# RCSS_PCR register map
Vendor: Texas Instruments
Registers are 32-bit, read-write, no defined reset value unless marked. A register's access mark holds for its fields unless they carry their own. Offsets are as the file gives them; [hi:lo] are bit positions; {n}, {i} and the like mark numbered series.

## RCSS_PCR (part 2 of 2)
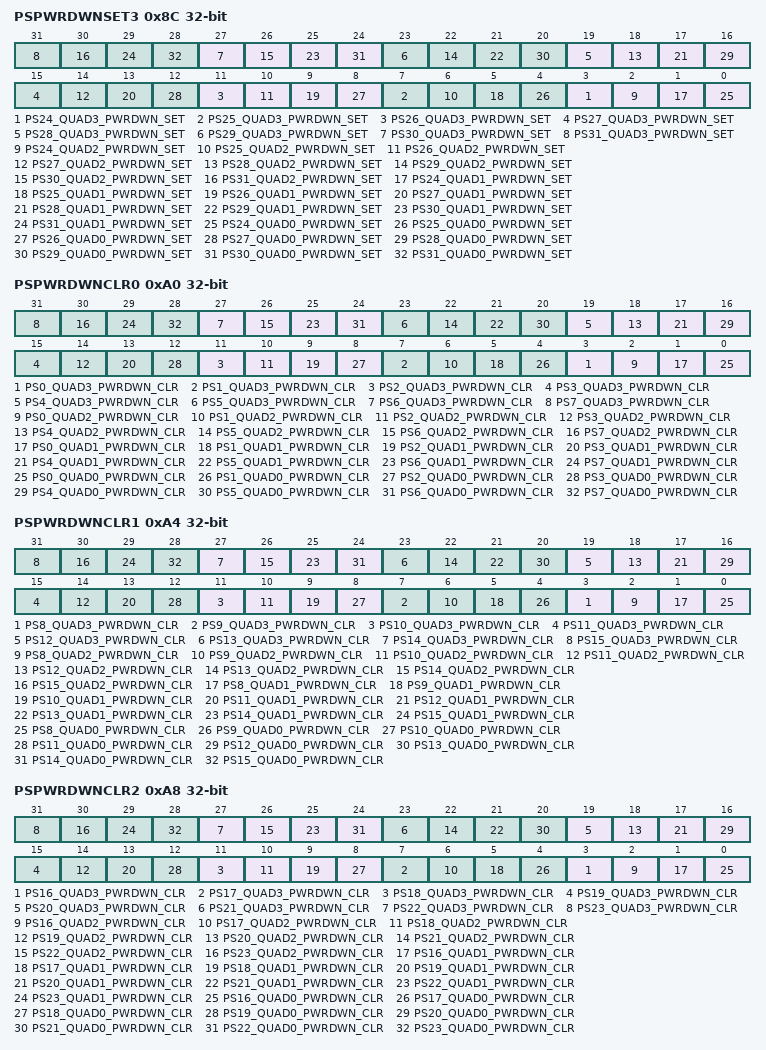
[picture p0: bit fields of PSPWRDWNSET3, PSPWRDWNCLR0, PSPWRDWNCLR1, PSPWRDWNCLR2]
0x8C PSPWRDWNSET3 — Set-only register to powerdown the applicable peripherals in the 32 quadrants of PS24 to PS31
  [4n-93] PS{n}_QUAD3_PWRDWN_SET (n=24..31) — Readable in both user and privileged modes. 1 = The clock to the peripheral starting at quadrant ‘m’ of the peripheral frame ‘n’ needs to be powered down. 0 = The clock to the peripheral starting at quadrant ‘m’ of the peripheral frame ‘n’ needs to be powered up. Writable only in privileged mode 1 = Sets the corresponding bit in PSPWRDWNSET3 and PSPWRDWNCLR3 registers 0 = Has no effect
  [4n-94] PS{n}_QUAD2_PWRDWN_SET (n=24..31) — Readable in both user and privileged modes. 1 = The clock to the peripheral starting at quadrant ‘m’ of the peripheral frame ‘n’ needs to be powered down. 0 = The clock to the peripheral starting at quadrant ‘m’ of the peripheral frame ‘n’ needs to be powered up. Writable only in privileged mode 1 = Sets the corresponding bit in PSPWRDWNSET3 and PSPWRDWNCLR3 registers 0 = Has no effect
  [4n-95] PS{n}_QUAD1_PWRDWN_SET (n=24..31) — Readable in both user and privileged modes. 1 = The clock to the peripheral starting at quadrant ‘m’ of the peripheral frame ‘n’ needs to be powered down. 0 = The clock to the peripheral starting at quadrant ‘m’ of the peripheral frame ‘n’ needs to be powered up. Writable only in privileged mode 1 = Sets the corresponding bit in PSPWRDWNSET3 and PSPWRDWNCLR3 registers 0 = Has no effect
  [4n-96] PS{n}_QUAD0_PWRDWN_SET (n=24..31) — Readable in both user and privileged modes. 1 = The clock to the peripheral starting at quadrant ‘m’ of the peripheral frame ‘n’ needs to be powered down. 0 = The clock to the peripheral starting at quadrant ‘m’ of the peripheral frame ‘n’ needs to be powered up. Writable only in privileged mode 1 = Sets the corresponding bit in PSPWRDWNSET3 and PSPWRDWNCLR3 registers 0 = Has no effect
0xA0 PSPWRDWNCLR0 — Clear-only register to deassert powerdown bits of the applicable peripherals in the 32 quadrants of PS0 to PS7
  [4n+3] PS{n}_QUAD3_PWRDWN_CLR (n=0..7) — Readable in both user and privileged modes. 1 = The clock to the peripheral starting at quadrant ‘m’ of the peripheral frame ‘n’ needs to be powered down. 0 = The clock to the peripheral starting at quadrant ‘m’ of the peripheral frame ‘n’ needs to be powered up. Writable only in privileged mode 1 = Clears the corresponding bit in PSPWRDWNSET0 and PSPWRDWNCLR0 registers 0 = Has no effect
  [4n+2] PS{n}_QUAD2_PWRDWN_CLR (n=0..7) — Readable in both user and privileged modes. 1 = The clock to the peripheral starting at quadrant ‘m’ of the peripheral frame ‘n’ needs to be powered down. 0 = The clock to the peripheral starting at quadrant ‘m’ of the peripheral frame ‘n’ needs to be powered up. Writable only in privileged mode 1 = Clears the corresponding bit in PSPWRDWNSET0 and PSPWRDWNCLR0 registers 0 = Has no effect
  [4n+1] PS{n}_QUAD1_PWRDWN_CLR (n=0..7) — Readable in both user and privileged modes. 1 = The clock to the peripheral starting at quadrant ‘m’ of the peripheral frame ‘n’ needs to be powered down. 0 = The clock to the peripheral starting at quadrant ‘m’ of the peripheral frame ‘n’ needs to be powered up. Writable only in privileged mode 1 = Clears the corresponding bit in PSPWRDWNSET0 and PSPWRDWNCLR0 registers 0 = Has no effect
  [4n] PS{n}_QUAD0_PWRDWN_CLR (n=0..7) — Readable in both user and privileged modes. 1 = The clock to the peripheral starting at quadrant ‘m’ of the peripheral frame ‘n’ needs to be powered down. 0 = The clock to the peripheral starting at quadrant ‘m’ of the peripheral frame ‘n’ needs to be powered up. Writable only in privileged mode 1 = Clears the corresponding bit in PSPWRDWNSET0 and PSPWRDWNCLR0 registers 0 = Has no effect
0xA4 PSPWRDWNCLR1 — Clear-only register to deassert powerdown bits of the applicable peripherals in the 32 quadrants of PS8 to PS15
  [4n-29] PS{n}_QUAD3_PWRDWN_CLR (n=8..15) — Readable in both user and privileged modes. 1 = The clock to the peripheral starting at quadrant ‘m’ of the peripheral frame ‘n’ needs to be powered down. 0 = The clock to the peripheral starting at quadrant ‘m’ of the peripheral frame ‘n’ needs to be powered up. Writable only in privileged mode 1 = Clears the corresponding bit in PSPWRDWNCLR1 and PSPWRDWNCLR1 registers 0 = Has no effect
  [4n-30] PS{n}_QUAD2_PWRDWN_CLR (n=8..15) — Readable in both user and privileged modes. 1 = The clock to the peripheral starting at quadrant ‘m’ of the peripheral frame ‘n’ needs to be powered down. 0 = The clock to the peripheral starting at quadrant ‘m’ of the peripheral frame ‘n’ needs to be powered up. Writable only in privileged mode 1 = Clears the corresponding bit in PSPWRDWNCLR1 and PSPWRDWNCLR1 registers 0 = Has no effect
  [4n-31] PS{n}_QUAD1_PWRDWN_CLR (n=8..15) — Readable in both user and privileged modes. 1 = The clock to the peripheral starting at quadrant ‘m’ of the peripheral frame ‘n’ needs to be powered down. 0 = The clock to the peripheral starting at quadrant ‘m’ of the peripheral frame ‘n’ needs to be powered up. Writable only in privileged mode 1 = Clears the corresponding bit in PSPWRDWNCLR1 and PSPWRDWNCLR1 registers 0 = Has no effect
  [4n-32] PS{n}_QUAD0_PWRDWN_CLR (n=8..15) — Readable in both user and privileged modes. 1 = The clock to the peripheral starting at quadrant ‘m’ of the peripheral frame ‘n’ needs to be powered down. 0 = The clock to the peripheral starting at quadrant ‘m’ of the peripheral frame ‘n’ needs to be powered up. Writable only in privileged mode 1 = Clears the corresponding bit in PSPWRDWNCLR1 and PSPWRDWNCLR1 registers 0 = Has no effect
0xA8 PSPWRDWNCLR2 — Clear-only register to deassert powerdown bits of the applicable peripherals in the 32 quadrants of PS16 to PS23
  [4n-61] PS{n}_QUAD3_PWRDWN_CLR (n=16..23) — Readable in both user and privileged modes. 1 = The clock to the peripheral starting at quadrant ‘m’ of the peripheral frame ‘n’ needs to be powered down. 0 = The clock to the peripheral starting at quadrant ‘m’ of the peripheral frame ‘n’ needs to be powered up. Writable only in privileged mode 1 = Clears the corresponding bit in PSPWRDWNSET2 and PSPWRDWNCLR2 registers 0 = Has no effect
  [4n-62] PS{n}_QUAD2_PWRDWN_CLR (n=16..23) — Readable in both user and privileged modes. 1 = The clock to the peripheral starting at quadrant ‘m’ of the peripheral frame ‘n’ needs to be powered down. 0 = The clock to the peripheral starting at quadrant ‘m’ of the peripheral frame ‘n’ needs to be powered up. Writable only in privileged mode 1 = Clears the corresponding bit in PSPWRDWNSET2 and PSPWRDWNCLR2 registers 0 = Has no effect
  [4n-63] PS{n}_QUAD1_PWRDWN_CLR (n=16..23) — Readable in both user and privileged modes. 1 = The clock to the peripheral starting at quadrant ‘m’ of the peripheral frame ‘n’ needs to be powered down. 0 = The clock to the peripheral starting at quadrant ‘m’ of the peripheral frame ‘n’ needs to be powered up. Writable only in privileged mode 1 = Clears the corresponding bit in PSPWRDWNSET2 and PSPWRDWNCLR2 registers 0 = Has no effect
  [4n-64] PS{n}_QUAD0_PWRDWN_CLR (n=16..23) — Readable in both user and privileged modes. 1 = The clock to the peripheral starting at quadrant ‘m’ of the peripheral frame ‘n’ needs to be powered down. 0 = The clock to the peripheral starting at quadrant ‘m’ of the peripheral frame ‘n’ needs to be powered up. Writable only in privileged mode 1 = Clears the corresponding bit in PSPWRDWNSET2 and PSPWRDWNCLR2 registers 0 = Has no effect
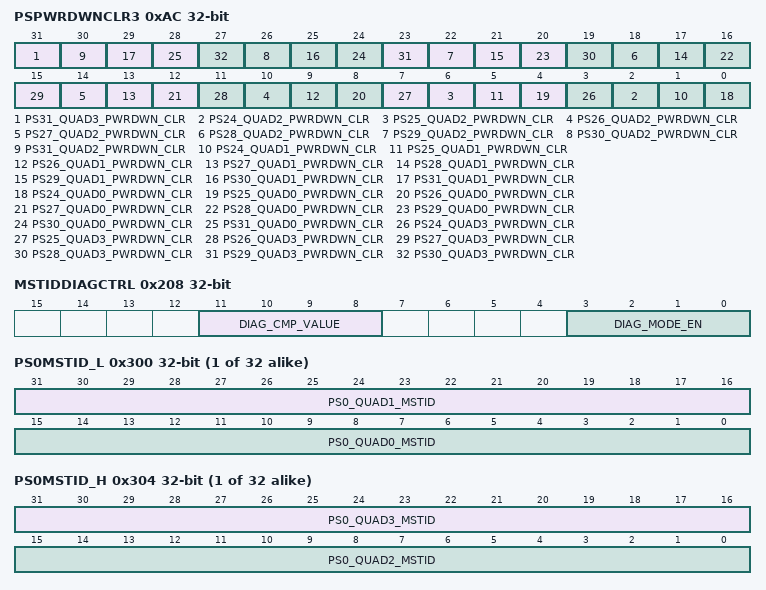
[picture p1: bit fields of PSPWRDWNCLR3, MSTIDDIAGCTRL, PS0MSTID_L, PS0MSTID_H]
0xAC PSPWRDWNCLR3 — Clear-only register to deassert powerdown bits of the applicable peripherals in the 32 quadrants of PS24 to PS31
  [31] PS31_QUAD3_PWRDWN_CLR
  [4n-94] PS{n}_QUAD2_PWRDWN_CLR (n=24..31) — Readable in both user and privileged modes. 1 = The clock to the peripheral starting at quadrant ‘m’ of the peripheral frame ‘n’ needs to be powered down. 0 = The clock to the peripheral starting at quadrant ‘m’ of the peripheral frame ‘n’ needs to be powered up. Writable only in privileged mode 1 = Clears the corresponding bit in PSPWRDWNSET3 and PSPWRDWNCLR3 registers 0 = Has no effect
  [4n-95] PS{n}_QUAD1_PWRDWN_CLR (n=24..31) — Readable in both user and privileged modes. 1 = The clock to the peripheral starting at quadrant ‘m’ of the peripheral frame ‘n’ needs to be powered down. 0 = The clock to the peripheral starting at quadrant ‘m’ of the peripheral frame ‘n’ needs to be powered up. Writable only in privileged mode 1 = Clears the corresponding bit in PSPWRDWNSET3 and PSPWRDWNCLR3 registers 0 = Has no effect
  [4n-96] PS{n}_QUAD0_PWRDWN_CLR (n=24..31) — Readable in both user and privileged modes. 1 = The clock to the peripheral starting at quadrant ‘m’ of the peripheral frame ‘n’ needs to be powered down. 0 = The clock to the peripheral starting at quadrant ‘m’ of the peripheral frame ‘n’ needs to be powered up. Writable only in privileged mode 1 = Clears the corresponding bit in PSPWRDWNSET3 and PSPWRDWNCLR3 registers 0 = Has no effect
  [4n-93] PS{n}_QUAD3_PWRDWN_CLR (n=24..30) — Readable in both user and privileged modes. 1 = The clock to the peripheral starting at quadrant ‘m’ of the peripheral frame ‘n’ needs to be powered down. 0 = The clock to the peripheral starting at quadrant ‘m’ of the peripheral frame ‘n’ needs to be powered up. Writable only in privileged mode 1 = Clears the corresponding bit in PSPWRDWNSET3 and PSPWRDWNCLR3 registers 0 = Has no effect
0xC0 PDPWRDWNSET access per field — Set-only register to powerdown the debug frame
  [0] PD_PWRDWN_SET rw — Readable in both user and privileged modes. 1 = Clock to the debug frame needs to be powered down. 0 = Clock to the debug frame needs to be powered up. Writable only in privileged mode 1 = Bit 0 when written 1, will get set in both PDPWRDWNSET and PDPWRDWNCLR registers. The other bits are not affected. 0 = Has no effect
0xC4 PDPWRDWNCLR access per field — Clear-only register to deassert the debug frame’s powerdown bit
  [0] PD_PWRDWN_CLR rw — Readable in both user and privileged modes. 1 = The clock to the debug frame needs to be powered down. 0 = The clock to the debug frame needs to be powered up. Writable only in privileged mode 1 = Bit 0 when written 1, will get cleared in both PDPWRDWNSET and PDPWRDWNCLR registers. The other bits are not affected. 0 = Has no effect
0x200 MSTIDWRENA access per field — MasterID Protection Write Enable Register
  [3:0] MSTIDREG_WRENA rw — Readable in both user and privileged modes. 1010 = All master-id registers are unlocked and available for write. others = Writes to all master-id registers are locked. Writable only in privileged mode 1010 = Writes to master-id registers are unlocked. others = Writes to master-id registers are locked.
0x204 MSTIDENA access per field — MasterID Protection Enable Register
  [3:0] MSTID_CHK_EN rw — Readable in both user and privileged modes. Writable only in privileged mode 1010 = Enable the master-id feature check. others = Master-id check is disabled.
0x208 MSTIDDIAGCTRL access per field — MasterID Diagnostic Control Register
  [11:8] DIAG_CMP_VALUE rw — MasterID diagnostic mode control register bits; 4-bit data which is compared with the master-id register of all defined frames during diagnostic mode. Any error in compare logic is indicated through AERROR output from PCR. Readable in both user and privileged modes. Reads the programmed value in diagnostic compare value field. Writable only in privileged mode
  [3:0] DIAG_MODE_EN rw — MasterID compare logic diagnostic mode enable bits; 4-bit key for enabling the master-id registers compare logic. Readable in both user and privileged modes. Writable only in privileged mode 1010 = Master-id compare diagnostic mode is enabled. others = Master-id compare diagnostic mode is disabled.
{0x300+8i} PS{i}MSTID_L (i=0..31) — Peripheral Frame Master-ID Protection Register{i}_L
  [31:16] PS{i}_QUAD1_MSTID — There are 16 bits for each quadrant in PS frame. These bits sets the permission for maximum of 16 masters to address the peripheral mapped in each of the quadrant. The following examples shows the usage of these register bits. (a) If bits 15:0 is 1010_1010_1010_1010, peripheral mapped in Quad0 can be addressed by Masters with Master-ID equals 1,3,5,7,9,11,13,15 (b) If bits 31:16 is 1100_1100_1100_1100, peripheral mapped in Quad1 can be addressed by Masters with Master-ID equals 2,3,6,7,10,11,14,15 Readable in both user and privileged modes. 1 = The peripheral mapped in the quadrant can be addressed by masters with matching Master-ID. 0 = The peipheral is locked for masters with matching Master-ID. PCR responds with AERROR. Writable only in privileged mode 1 = Sets the corresponding bit. 0 = Clears the corresponding bit. Writes to unimplemented bits have no effect and reads yield 0.
  [15:0] PS{i}_QUAD0_MSTID — There are 16 bits for each quadrant in PS frame. These bits sets the permission for maximum of 16 masters to address the peripheral mapped in each of the quadrant. The following examples shows the usage of these register bits. (a) If bits 15:0 is 1010_1010_1010_1010, peripheral mapped in Quad0 can be addressed by Masters with Master-ID equals 1,3,5,7,9,11,13,15 (b) If bits 31:16 is 1100_1100_1100_1100, peripheral mapped in Quad1 can be addressed by Masters with Master-ID equals 2,3,6,7,10,11,14,15 Readable in both user and privileged modes. 1 = The peripheral mapped in the quadrant can be addressed by masters with matching Master-ID. 0 = The peipheral is locked for masters with matching Master-ID. PCR responds with AERROR. Writable only in privileged mode 1 = Sets the corresponding bit. 0 = Clears the corresponding bit. Writes to unimplemented bits have no effect and reads yield 0.
{0x304+8i} PS{i}MSTID_H (i=0..31) — Peripheral Frame Master-ID Protection Register{i}_H
  [31:16] PS{i}_QUAD3_MSTID — There are 16 bits for each quadrant in PS frame. These bits sets the permission for maximum of 16 masters to address the peripheral mapped in each of the quadrant. The following examples shows the usage of these register bits. (a) If bits 15:0 is 1010_1010_1010_1010, peripheral mapped in Quad0 can be addressed by Masters with Master-ID equals 1,3,5,7,9,11,13,15 (b) If bits 31:16 is 1100_1100_1100_1100, peripheral mapped in Quad1 can be addressed by Masters with Master-ID equals 2,3,6,7,10,11,14,15 Readable in both user and privileged modes. 1 = The peripheral mapped in the quadrant can be addressed by masters with matching Master-ID. 0 = The peipheral is locked for masters with matching Master-ID. PCR responds with AERROR. Writable only in privileged mode 1 = Sets the corresponding bit. 0 = Clears the corresponding bit. Writes to unimplemented bits have no effect and reads yield 0.
  [15:0] PS{i}_QUAD2_MSTID — There are 16 bits for each quadrant in PS frame. These bits sets the permission for maximum of 16 masters to address the peripheral mapped in each of the quadrant. The following examples shows the usage of these register bits. (a) If bits 15:0 is 1010_1010_1010_1010, peripheral mapped in Quad0 can be addressed by Masters with Master-ID equals 1,3,5,7,9,11,13,15 (b) If bits 31:16 is 1100_1100_1100_1100, peripheral mapped in Quad1 can be addressed by Masters with Master-ID equals 2,3,6,7,10,11,14,15 Readable in both user and privileged modes. 1 = The peripheral mapped in the quadrant can be addressed by masters with matching Master-ID. 0 = The peipheral is locked for masters with matching Master-ID. PCR responds with AERROR. Writable only in privileged mode 1 = Sets the corresponding bit. 0 = Clears the corresponding bit. Writes to unimplemented bits have no effect and reads yield 0.
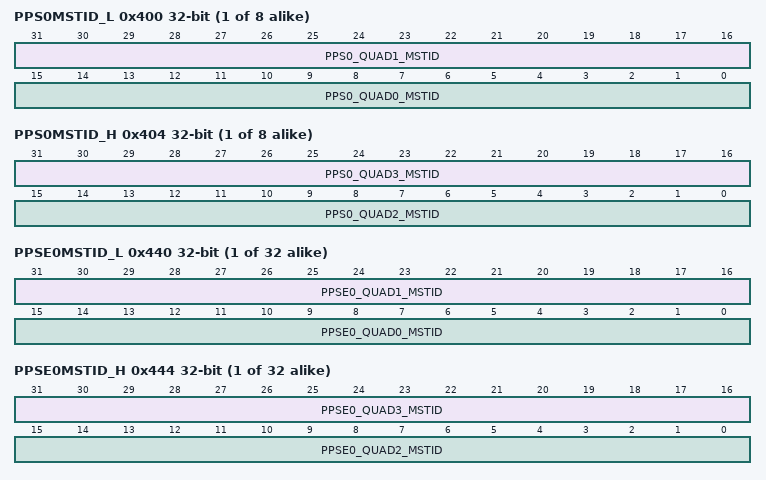
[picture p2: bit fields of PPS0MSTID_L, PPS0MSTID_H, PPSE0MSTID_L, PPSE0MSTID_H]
{0x400+8i} PPS{i}MSTID_L (i=0..7) — Privileged Peripheral Frame Master-ID Protection Register{i}_L
  [31:16] PPS{i}_QUAD1_MSTID — There are 16 bits for each quadrant in PPS frame. These bits set the permission for maximum of 16 masters to address the peripheral mapped in each of the quadrant. The scheme is similar to the one described for PS MSTID register in section 1.7.30. Readable in both user and privileged modes. 1 = The peripheral mapped in the quadrant can be addressed by master with matching Master-ID. 0 = The peripheral is locked for master with matching Master-ID. PCR responds with AERROR. Writable only in privileged mode 1 = Sets the corresponding bit. 0 = Clears the corresponding bit. Writes to unimplemented bits have no effect and reads yield 0.
  [15:0] PPS{i}_QUAD0_MSTID — There are 16 bits for each quadrant in PPS frame. These bits set the permission for maximum of 16 masters to address the peripheral mapped in each of the quadrant. The scheme is similar to the one described for PS MSTID register in section 1.7.30. Readable in both user and privileged modes. 1 = The peripheral mapped in the quadrant can be addressed by master with matching Master-ID. 0 = The peripheral is locked for master with matching Master-ID. PCR responds with AERROR. Writable only in privileged mode 1 = Sets the corresponding bit. 0 = Clears the corresponding bit. Writes to unimplemented bits have no effect and reads yield 0.
{0x404+8i} PPS{i}MSTID_H (i=0..7) — Privileged Peripheral Frame Master-ID Protection Register{i}_H
  [31:16] PPS{i}_QUAD3_MSTID — There are 16 bits for each quadrant in PPS frame. These bits set the permission for maximum of 16 masters to address the peripheral mapped in each of the quadrant. The scheme is similar to the one described for PS MSTID register in section 1.7.30. Readable in both user and privileged modes. 1 = The peripheral mapped in the quadrant can be addressed by master with matching Master-ID. 0 = The peripheral is locked for master with matching Master-ID. PCR responds with AERROR. Writable only in privileged mode 1 = Sets the corresponding bit. 0 = Clears the corresponding bit. Writes to unimplemented bits have no effect and reads yield 0.
  [15:0] PPS{i}_QUAD2_MSTID — There are 16 bits for each quadrant in PPS frame. These bits set the permission for maximum of 16 masters to address the peripheral mapped in each of the quadrant. The scheme is similar to the one described for PS MSTID register in section 1.7.30. Readable in both user and privileged modes. 1 = The peripheral mapped in the quadrant can be addressed by master with matching Master-ID. 0 = The peripheral is locked for master with matching Master-ID. PCR responds with AERROR. Writable only in privileged mode 1 = Sets the corresponding bit. 0 = Clears the corresponding bit. Writes to unimplemented bits have no effect and reads yield 0.
{0x440+8i} PPSE{i}MSTID_L (i=0..31) — Privileged Peripheral Extended Frame Master-ID Protection Register{i}_L
  [31:16] PPSE{i}_QUAD1_MSTID — There are 16 bits for each quadrant in PPSE frame. These bits set the permission for maximum of 16 masters to address the peripheral mapped in each of the quadrant. The scheme is similar to the one described for PS MSTID in section 1.7.30. Readable in both user and privileged modes. 1 = The peripheral mapped in the quadrant can be addressed by master with matching Master-ID. 0 = The peripheral is locked for master with matching Master-ID. PCR responds with AERROR. Writable only in privileged mode 1 = Sets the corresponding bit. 0 = Clears the corresponding bit. Writes to unimplemented bits have no effect and reads yield 0.
  [15:0] PPSE{i}_QUAD0_MSTID — There are 16 bits for each quadrant in PPSE frame. These bits set the permission for maximum of 16 masters to address the peripheral mapped in each of the quadrant. The scheme is similar to the one described for PS MSTID in section 1.7.30. Readable in both user and privileged modes. 1 = The peripheral mapped in the quadrant can be addressed by master with matching Master-ID. 0 = The peripheral is locked for master with matching Master-ID. PCR responds with AERROR. Writable only in privileged mode 1 = Sets the corresponding bit. 0 = Clears the corresponding bit. Writes to unimplemented bits have no effect and reads yield 0.
{0x444+8i} PPSE{i}MSTID_H (i=0..31) — Privileged Peripheral Extended Frame Master-ID Protection Register{i}_H
  [31:16] PPSE{i}_QUAD3_MSTID — There are 16 bits for each quadrant in PPSE frame. These bits set the permission for maximum of 16 masters to address the peripheral mapped in each of the quadrant. The scheme is similar to the one described for PS MSTID in section 1.7.30. Readable in both user and privileged modes. 1 = The peripheral mapped in the quadrant can be addressed by master with matching Master-ID. 0 = The peripheral is locked for master with matching Master-ID. PCR responds with AERROR. Writable only in privileged mode 1 = Sets the corresponding bit. 0 = Clears the corresponding bit. Writes to unimplemented bits have no effect and reads yield 0.
  [15:0] PPSE{i}_QUAD2_MSTID — There are 16 bits for each quadrant in PPSE frame. These bits set the permission for maximum of 16 masters to address the peripheral mapped in each of the quadrant. The scheme is similar to the one described for PS MSTID in section 1.7.30. Readable in both user and privileged modes. 1 = The peripheral mapped in the quadrant can be addressed by master with matching Master-ID. 0 = The peripheral is locked for master with matching Master-ID. PCR responds with AERROR. Writable only in privileged mode 1 = Sets the corresponding bit. 0 = Clears the corresponding bit. Writes to unimplemented bits have no effect and reads yield 0.
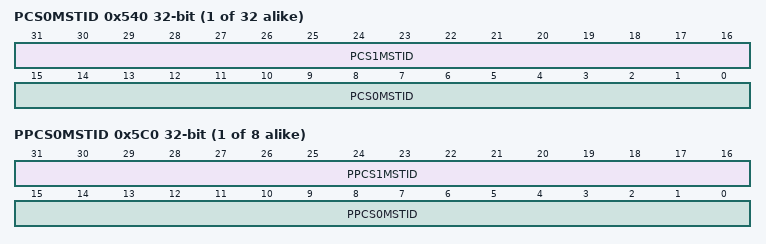
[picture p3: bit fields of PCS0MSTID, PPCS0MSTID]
{0x540+4i} PCS{i}MSTID (i=0..31) — Memory Frame Master ID Protection Register{i}
  [31:16] PCS{2i+1}MSTID — There are 16 bits for each frame in PCS. These bits sets the permission for maximum of 16 masters to address the memory mapped in each of the frame. The following examples shows the usage of these register bits. (a) If bits 15:0 is 1010_1010_1010_1010, memory frame mapped to PCSm can be addressed by Masters with Master-ID equals 1,3,5,7,9,11,13,15. (b) If bits 31:24 is 1100_1100_1100_1100, memory frame mapped to PCS(m+1) can be addressed by Masters with Master-ID equals 2,3,6,7,10,11,14,15. Readable in both user and privileged modes. 1 = The memory mapped in respective frames can be addressed by master with matching Master-ID. 0 = The memory is locked for master with matching Master-ID. PCR responds with AERRORr. Writable only in privileged mode 1 = Sets the corresponding bit. 0 = Clears the corresponding bit. Writes to unimplemented bits have no effect and reads yield 0
  [15:0] PCS{2i}MSTID — There are 16 bits for each frame in PCS. These bits sets the permission for maximum of 16 masters to address the memory mapped in each of the frame. The following examples shows the usage of these register bits. (a) If bits 15:0 is 1010_1010_1010_1010, memory frame mapped to PCSm can be addressed by Masters with Master-ID equals 1,3,5,7,9,11,13,15. (b) If bits 31:24 is 1100_1100_1100_1100, memory frame mapped to PCS(m+1) can be addressed by Masters with Master-ID equals 2,3,6,7,10,11,14,15. Readable in both user and privileged modes. 1 = The memory mapped in respective frames can be addressed by master with matching Master-ID. 0 = The memory is locked for master with matching Master-ID. PCR responds with AERRORr. Writable only in privileged mode 1 = Sets the corresponding bit. 0 = Clears the corresponding bit. Writes to unimplemented bits have no effect and reads yield 0
{0x5C0+4i} PPCS{i}MSTID (i=0..7) — Memory Frame Master ID Protection Register{i+32}
  [31:16] PPCS{2i+1}MSTID — There are 16 bits for each frame in PPCS. These bits sets the permission for maximum of 16 masters to address the memory mapped in each of the frame. The scheme is similar to the one described for PCSm MSTID in section 1.7.33. Readable in both user and privileged modes. 1 = The memory mapped in respective frames can be addressed by master with matching Master-ID. 0 = The memory is locked for master with matching Master-ID. PCR responds with AERROR. Writable only in privileged mode 1 = Sets the corresponding bit. 0 = Clears the corresponding bit. Writes to unimplemented bits have no effect and reads yield 0.
  [15:0] PPCS{2i}MSTID — There are 16 bits for each frame in PPCS. These bits sets the permission for maximum of 16 masters to address the memory mapped in each of the frame. The scheme is similar to the one described for PCSm MSTID in section 1.7.33. Readable in both user and privileged modes. 1 = The memory mapped in respective frames can be addressed by master with matching Master-ID. 0 = The memory is locked for master with matching Master-ID. PCR responds with AERROR. Writable only in privileged mode 1 = Sets the corresponding bit. 0 = Clears the corresponding bit. Writes to unimplemented bits have no effect and reads yield 0.
0x5E0 PCREXTMSTID — Master-ID Protection Register for external PCR
  [31:0] PCREXT_MSTID — These bits sets the permission for maximum of 16 masters to address the external PCR frame. The scheme is similar to the one described for PCSm MSTID in section 1.7.33. Readable in both user and privileged modes. 1 = The memory mapped in respective frames can be addressed by master with matching Master-ID. 0 = The memory is locked for master with matching Master-ID. PCR responds with AERROR. Writable only in privileged mode 1 = Sets the corresponding bit. 0 = Clears the corresponding bit. Writes to unimplemented bits have no effect and reads yield 0.
